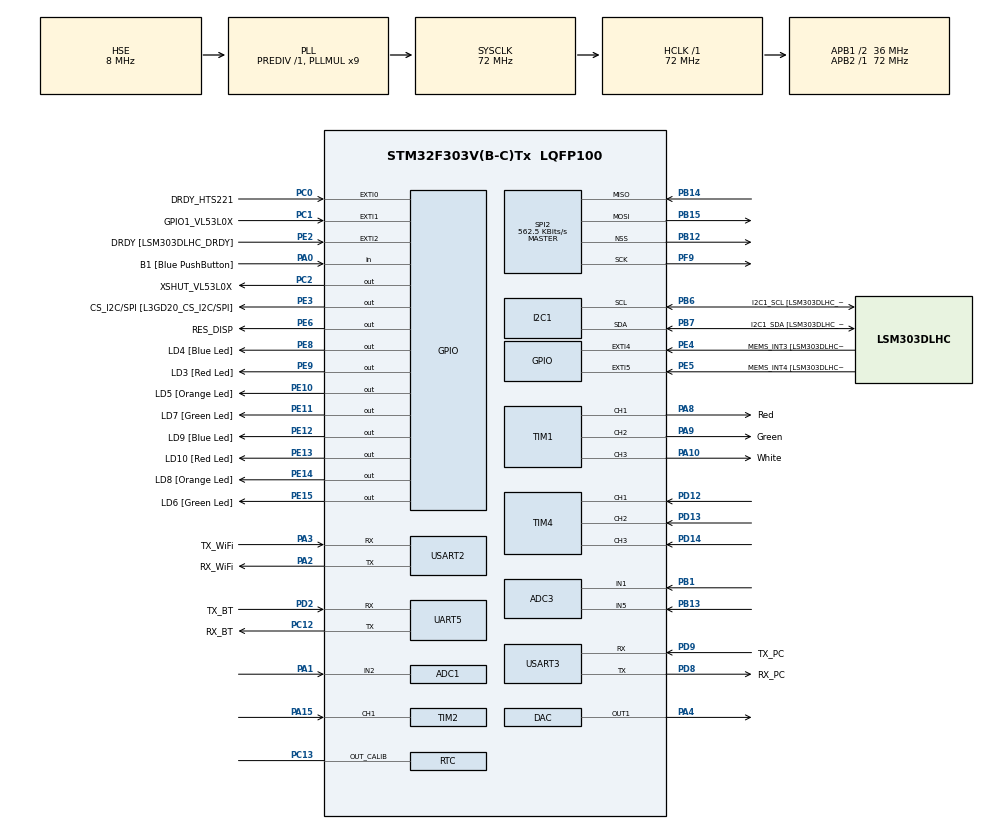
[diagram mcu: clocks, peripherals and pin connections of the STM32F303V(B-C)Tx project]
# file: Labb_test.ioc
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ADC1.Channel-0\#ChannelRegularConversion=ADC_CHANNEL_2
ADC1.NbrOfConversionFlag=1
ADC1.Offset-0\#ChannelRegularConversion=0
ADC1.OffsetNumber-0\#ChannelRegularConversion=ADC_OFFSET_NONE
ADC1.Rank-0\#ChannelRegularConversion=1
ADC1.SamplingTime-0\#ChannelRegularConversion=ADC_SAMPLETIME_1CYCLE_5
ADC1.master=1
ADC3.Channel-0\#ChannelRegularConversion=ADC_CHANNEL_1
ADC3.NbrOfConversionFlag=1
ADC3.Offset-0\#ChannelRegularConversion=0
ADC3.OffsetNumber-0\#ChannelRegularConversion=ADC_OFFSET_NONE
ADC3.Rank-0\#ChannelRegularConversion=1
ADC3.SamplingTime-0\#ChannelRegularConversion=ADC_SAMPLETIME_1CYCLE_5
ADC3.master=1
I2C1.Timing-I2C=0x2000090E
Mcu.Family=STM32F3
Mcu.Name=STM32F303V(B-C)Tx
Mcu.Package=LQFP100
NVIC.PriorityGroup=NVIC_PRIORITYGROUP_0
PA0.GPIO_Label=B1 [Blue PushButton]
PA0.Signal=GPIO_Input
PA1.Mode=IN2-Single-Ended
PA1.Signal=ADC1_IN2
PA10.GPIO_Label=White
PA10.Signal=S_TIM1_CH3
PA11.GPIO_Label=DM
PA11.Signal=USB_DM
PA12.GPIO_Label=DP
PA12.Signal=USB_DP
PA13.GPIO_Label=SWDIO
PA13.Mode=Serial_Wire
PA13.Signal=SYS_JTMS-SWDIO
PA14.GPIO_Label=SWCLK
PA14.Mode=Serial_Wire
PA14.Signal=SYS_JTCK-SWCLK
PA15.Signal=S_TIM2_CH1_ETR
PA2.GPIO_Label=RX_WiFi
PA2.Mode=Asynchronous
PA2.Signal=USART2_TX
PA3.GPIO_Label=TX_WiFi
PA3.Mode=Asynchronous
PA3.Signal=USART2_RX
PA4.Signal=COMP_DAC1_group
PA5.GPIO_Label=SPI1_SCK [L3GD20_SCL/SPC]
PA5.Signal=SPI1_SCK
PA6.GPIO_Label=SPI1_MISO [L3GD20_SA0/SDO]
PA6.Signal=SPI1_MISO
PA7.GPIO_Label=SPI1_MISO [L3GD20_SDA/SDI/SDO]
PA7.Signal=SPI1_MOSI
PA8.GPIO_Label=Red
PA8.Signal=S_TIM1_CH1
PA9.GPIO_Label=Green
PA9.Signal=S_TIM1_CH2
PB1.Mode=IN1-Single-Ended
PB1.Signal=ADC3_IN1
PB12.Mode=NSS_Signal_Hard_Output
PB12.Signal=SPI2_NSS
PB13.Mode=IN5-Single-Ended
PB13.Signal=ADC3_IN5
PB14.Mode=Full_Duplex_Master
PB14.Signal=SPI2_MISO
PB15.Mode=Full_Duplex_Master
PB15.Signal=SPI2_MOSI
PB3.GPIO_Label=SWO
PB3.Signal=SYS_JTDO-TRACESWO
PB6.GPIO_Label=I2C1_SCL [LSM303DLHC_SCL]
PB6.Mode=I2C
PB6.Signal=I2C1_SCL
PB7.GPIO_Label=I2C1_SDA [LSM303DLHC_SDA]
PB7.Mode=I2C
PB7.Signal=I2C1_SDA
PC0.GPIO_Label=DRDY_HTS221
PC0.Signal=GPXTI0
PC1.GPIO_Label=GPIO1_VL53L0X
PC1.Signal=GPXTI1
PC12.GPIO_Label=RX_BT
PC12.Mode=Asynchronous
PC12.Signal=UART5_TX
PC13.Mode=Calibration_1Hz
PC13.Signal=RTC_OUT_CALIB
PC14-OSC32_IN.GPIO_Label=OSC32_IN
PC14-OSC32_IN.Mode=LSE-External-Oscillator
PC14-OSC32_IN.Signal=RCC_OSC32_IN
PC15-OSC32_OUT.GPIO_Label=OSC32_OUT
PC15-OSC32_OUT.Mode=LSE-External-Oscillator
PC15-OSC32_OUT.Signal=RCC_OSC32_OUT
PC2.GPIO_Label=XSHUT_VL53L0X
PC2.Signal=GPIO_Output
PD12.Signal=S_TIM4_CH1
PD13.Signal=S_TIM4_CH2
PD14.Signal=S_TIM4_CH3
PD2.GPIO_Label=TX_BT
PD2.Mode=Asynchronous
PD2.Signal=UART5_RX
PD8.GPIO_Label=RX_PC
PD8.Mode=Asynchronous
PD8.Signal=USART3_TX
PD9.GPIO_Label=TX_PC
PD9.Mode=Asynchronous
PD9.Signal=USART3_RX
PE10.GPIO_Label=LD5 [Orange Led]
PE10.Signal=GPIO_Output
PE11.GPIO_Label=LD7 [Green Led]
PE11.Signal=GPIO_Output
PE12.GPIO_Label=LD9 [Blue Led]
PE12.Signal=GPIO_Output
PE13.GPIO_Label=LD10 [Red Led]
PE13.Signal=GPIO_Output
PE14.GPIO_Label=LD8 [Orange Led]
PE14.Signal=GPIO_Output
PE15.GPIO_Label=LD6 [Green Led]
PE15.Signal=GPIO_Output
PE2.GPIO_Label=DRDY [LSM303DLHC_DRDY]
PE2.GPIO_ModeDefaultEXTI=GPIO_MODE_EVT_RISING
PE2.Signal=GPXTI2
PE3.GPIO_Label=CS_I2C/SPI [L3GD20_CS_I2C/SPI]
PE3.Signal=GPIO_Output
PE4.GPIO_Label=MEMS_INT3 [LSM303DLHC_INT1]
PE4.GPIO_ModeDefaultEXTI=GPIO_MODE_EVT_RISING
PE4.Signal=GPXTI4
PE5.GPIO_Label=MEMS_INT4 [LSM303DLHC_INT2]
PE5.GPIO_ModeDefaultEXTI=GPIO_MODE_EVT_RISING
PE5.Signal=GPXTI5
PE6.GPIO_Label=RES_DISP
PE6.Signal=GPIO_Output
PE8.GPIO_Label=LD4 [Blue Led]
PE8.Signal=GPIO_Output
PE9.GPIO_Label=LD3 [Red Led]
PE9.Signal=GPIO_Output
PF0-OSC_IN.GPIO_Label=OSC_IN
PF0-OSC_IN.Mode=HSE-External-Oscillator
PF0-OSC_IN.Signal=RCC_OSC_IN
PF1-OSC_OUT.GPIO_Label=OSC_OUT
PF1-OSC_OUT.Mode=HSE-External-Oscillator
PF1-OSC_OUT.Signal=RCC_OSC_OUT
PF9.Mode=Full_Duplex_Master
PF9.Signal=SPI2_SCK
ProjectManager.HeapSize=0x200
ProjectManager.StackSize=0x400
ProjectManager.TargetToolchain=EWARM V8
RCC.AHBFreq_Value=72000000
RCC.APB1CLKDivider=RCC_HCLK_DIV2
RCC.APB1Freq_Value=36000000
RCC.APB1TimFreq_Value=72000000
RCC.APB2Freq_Value=72000000
RCC.APB2TimFreq_Value=72000000
RCC.CortexFreq_Value=72000000
RCC.HCLKFreq_Value=72000000
RCC.HSE_VALUE=8000000
RCC.HSI_VALUE=8000000
RCC.PLLMUL=RCC_PLL_MUL9
RCC.PLLSourceVirtual=RCC_PLLSOURCE_HSE
RCC.SYSCLKFreq_VALUE=72000000
RCC.SYSCLKSourceVirtual=RCC_SYSCLKSOURCE_PLLCLK
RCC.USBFreq_Value=72000000
SH.COMP_DAC1_group.0=DAC_OUT1,DAC_OUT1
SH.S_TIM1_CH1.0=TIM1_CH1,Output Compare1 CH1
SH.S_TIM1_CH2.0=TIM1_CH2,Output Compare2 CH2
SH.S_TIM1_CH3.0=TIM1_CH3,Output Compare3 CH3
SH.S_TIM2_CH1_ETR.0=TIM2_CH1,Input_Capture1_from_TI1
SH.S_TIM4_CH1.0=TIM4_CH1,Input_Capture1_from_TI1
SH.S_TIM4_CH2.0=TIM4_CH2,Input_Capture2_from_TI2
SH.S_TIM4_CH3.0=TIM4_CH3,Input_Capture3_from_TI3
SPI2.BaudRatePrescaler=SPI_BAUDRATEPRESCALER_64
SPI2.CLKPhase=SPI_PHASE_2EDGE
SPI2.CLKPolarity=SPI_POLARITY_HIGH
SPI2.CalculateBaudRate=562.5 KBits/s
SPI2.DataSize=SPI_DATASIZE_8BIT
SPI2.Direction=SPI_DIRECTION_2LINES
SPI2.FirstBit=SPI_FIRSTBIT_LSB
SPI2.Mode=SPI_MODE_MASTER
SPI2.VirtualNSS=VM_NSSHARD
SPI2.VirtualType=VM_MASTER
TIM1.Channel-Output\ Compare1\ CH1=TIM_CHANNEL_1
TIM1.Channel-Output\ Compare2\ CH2=TIM_CHANNEL_2
TIM1.Channel-Output\ Compare3\ CH3=TIM_CHANNEL_3
TIM2.Channel-Input_Capture1_from_TI1=TIM_CHANNEL_1
TIM4.Channel-Input_Capture1_from_TI1=TIM_CHANNEL_1
TIM4.Channel-Input_Capture2_from_TI2=TIM_CHANNEL_2
TIM4.Channel-Input_Capture3_from_TI3=TIM_CHANNEL_3
USART2.VirtualMode-Asynchronous=VM_ASYNC
USART3.VirtualMode-Asynchronous=VM_ASYNC
VP_RTC_VS_RTC_Activate.Mode=RTC_Enabled
board=STM32F3DISCOVERY

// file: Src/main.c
/**
  ******************************************************************************
  * @file           : main.c
  * @brief          : Main program body
  ******************************************************************************
  ** This notice applies to any and all portions of this file
  * that are not between comment pairs USER CODE BEGIN and
  * USER CODE END. Other portions of this file, whether
  * inserted by the user or by software development tools
  * are owned by their respective copyright owners.
  *
  * COPYRIGHT(c) 2019 STMicroelectronics
  *
  * Redistribution and use in source and binary forms, with or without modification,
  * are permitted provided that the following conditions are met:
  *   1. Redistributions of source code must retain the above copyright notice,
  *      this list of conditions and the following disclaimer.
  *   2. Redistributions in binary form must reproduce the above copyright notice,
  *      this list of conditions and the following disclaimer in the documentation
  *      and/or other materials provided with the distribution.
  *   3. Neither the name of STMicroelectronics nor the names of its contributors
  *      may be used to endorse or promote products derived from this software
  *      without specific prior written permission.
  *
  * THIS SOFTWARE IS PROVIDED BY THE COPYRIGHT HOLDERS AND CONTRIBUTORS "AS IS"
  * AND ANY EXPRESS OR IMPLIED WARRANTIES, INCLUDING, BUT NOT LIMITED TO, THE
  * IMPLIED WARRANTIES OF MERCHANTABILITY AND FITNESS FOR A PARTICULAR PURPOSE ARE
  * DISCLAIMED. IN NO EVENT SHALL THE COPYRIGHT HOLDER OR CONTRIBUTORS BE LIABLE
  * FOR ANY DIRECT, INDIRECT, INCIDENTAL, SPECIAL, EXEMPLARY, OR CONSEQUENTIAL
  * DAMAGES (INCLUDING, BUT NOT LIMITED TO, PROCUREMENT OF SUBSTITUTE GOODS OR
  * SERVICES; LOSS OF USE, DATA, OR PROFITS; OR BUSINESS INTERRUPTION) HOWEVER
  * CAUSED AND ON ANY THEORY OF LIABILITY, WHETHER IN CONTRACT, STRICT LIABILITY,
  * OR TORT (INCLUDING NEGLIGENCE OR OTHERWISE) ARISING IN ANY WAY OUT OF THE USE
  * OF THIS SOFTWARE, EVEN IF ADVISED OF THE POSSIBILITY OF SUCH DAMAGE.
  *
  ******************************************************************************
  */
#include "main.h"
#include "stm32f3xx_hal.h"

ADC_HandleTypeDef hadc1;
ADC_HandleTypeDef hadc3;

DAC_HandleTypeDef hdac;

I2C_HandleTypeDef hi2c1;

RTC_HandleTypeDef hrtc;

SPI_HandleTypeDef hspi2;

TIM_HandleTypeDef htim1;
TIM_HandleTypeDef htim2;
TIM_HandleTypeDef htim4;

UART_HandleTypeDef huart5;
UART_HandleTypeDef huart2;
UART_HandleTypeDef huart3;

/* USER CODE BEGIN PV */
/* Private variables ---------------------------------------------------------*/

/* USER CODE END PV */

void SystemClock_Config(void);
static void MX_GPIO_Init(void);
static void MX_I2C1_Init(void);
static void MX_TIM2_Init(void);
static void MX_ADC3_Init(void);
static void MX_ADC1_Init(void);
static void MX_UART5_Init(void);
static void MX_USART2_UART_Init(void);
static void MX_SPI2_Init(void);
static void MX_TIM1_Init(void);
static void MX_TIM4_Init(void);
static void MX_USART3_UART_Init(void);
static void MX_DAC_Init(void);
static void MX_RTC_Init(void);

void HAL_TIM_MspPostInit(TIM_HandleTypeDef *htim);

/* USER CODE BEGIN PFP */
/* Private function prototypes -----------------------------------------------*/

/* USER CODE END PFP */

int main(void)
{

  /* MCU Configuration----------------------------------------------------------*/

  /* Reset of all peripherals, Initializes the Flash interface and the Systick. */
  HAL_Init();

  /* Configure the system clock */
  SystemClock_Config();

  /* Initialize all configured peripherals */
  MX_GPIO_Init();
  MX_I2C1_Init();
  MX_TIM2_Init();
  MX_ADC3_Init();
  MX_ADC1_Init();
  MX_UART5_Init();
  MX_USART2_UART_Init();
  MX_SPI2_Init();
  MX_TIM1_Init();
  MX_TIM4_Init();
  MX_USART3_UART_Init();
  MX_DAC_Init();
  MX_RTC_Init();
  /* USER CODE BEGIN 2 */

    initDisplay();
    sendDisplay(0,0,0);

  /* USER CODE END 2 */

  /* Infinite loop */
  while (1)
  {

  }

}

void SystemClock_Config(void)
{

  RCC_OscInitTypeDef RCC_OscInitStruct;
  RCC_ClkInitTypeDef RCC_ClkInitStruct;
  RCC_PeriphCLKInitTypeDef PeriphClkInit;

    /**Initializes the CPU, AHB and APB busses clocks
    */
  RCC_OscInitStruct.OscillatorType = RCC_OSCILLATORTYPE_HSI|RCC_OSCILLATORTYPE_LSI
                              |RCC_OSCILLATORTYPE_HSE;
  RCC_OscInitStruct.HSEState = RCC_HSE_ON;
  RCC_OscInitStruct.HSEPredivValue = RCC_HSE_PREDIV_DIV1;
  RCC_OscInitStruct.HSIState = RCC_HSI_ON;
  RCC_OscInitStruct.HSICalibrationValue = 16;
  RCC_OscInitStruct.LSIState = RCC_LSI_ON;
  RCC_OscInitStruct.PLL.PLLState = RCC_PLL_ON;
  RCC_OscInitStruct.PLL.PLLSource = RCC_PLLSOURCE_HSE;
  RCC_OscInitStruct.PLL.PLLMUL = RCC_PLL_MUL9;
  if (HAL_RCC_OscConfig(&RCC_OscInitStruct) != HAL_OK)
  {
    _Error_Handler(__FILE__, __LINE__);
  }

    /**Initializes the CPU, AHB and APB busses clocks
    */
  RCC_ClkInitStruct.ClockType = RCC_CLOCKTYPE_HCLK|RCC_CLOCKTYPE_SYSCLK
                              |RCC_CLOCKTYPE_PCLK1|RCC_CLOCKTYPE_PCLK2;
  RCC_ClkInitStruct.SYSCLKSource = RCC_SYSCLKSOURCE_PLLCLK;
  RCC_ClkInitStruct.AHBCLKDivider = RCC_SYSCLK_DIV1;
  RCC_ClkInitStruct.APB1CLKDivider = RCC_HCLK_DIV2;
  RCC_ClkInitStruct.APB2CLKDivider = RCC_HCLK_DIV1;

  if (HAL_RCC_ClockConfig(&RCC_ClkInitStruct, FLASH_LATENCY_2) != HAL_OK)
  {
    _Error_Handler(__FILE__, __LINE__);
  }

  PeriphClkInit.PeriphClockSelection = RCC_PERIPHCLK_USART2|RCC_PERIPHCLK_USART3
                              |RCC_PERIPHCLK_UART5|RCC_PERIPHCLK_I2C1
                              |RCC_PERIPHCLK_RTC|RCC_PERIPHCLK_TIM1
                              |RCC_PERIPHCLK_ADC12|RCC_PERIPHCLK_ADC34;
  PeriphClkInit.Usart2ClockSelection = RCC_USART2CLKSOURCE_PCLK1;
  PeriphClkInit.Usart3ClockSelection = RCC_USART3CLKSOURCE_PCLK1;
  PeriphClkInit.Uart5ClockSelection = RCC_UART5CLKSOURCE_PCLK1;
  PeriphClkInit.Adc12ClockSelection = RCC_ADC12PLLCLK_DIV1;
  PeriphClkInit.Adc34ClockSelection = RCC_ADC34PLLCLK_DIV1;
  PeriphClkInit.I2c1ClockSelection = RCC_I2C1CLKSOURCE_HSI;
  PeriphClkInit.RTCClockSelection = RCC_RTCCLKSOURCE_LSI;
  PeriphClkInit.Tim1ClockSelection = RCC_TIM1CLK_HCLK;
  if (HAL_RCCEx_PeriphCLKConfig(&PeriphClkInit) != HAL_OK)
  {
    _Error_Handler(__FILE__, __LINE__);
  }

    /**Configure the Systick interrupt time
    */
  HAL_SYSTICK_Config(HAL_RCC_GetHCLKFreq()/1000);

    /**Configure the Systick
    */
  HAL_SYSTICK_CLKSourceConfig(SYSTICK_CLKSOURCE_HCLK);

  /* SysTick_IRQn interrupt configuration */
  HAL_NVIC_SetPriority(SysTick_IRQn, 0, 0);
}
   uint8_t data[3]={0x00,0x00,0x00};

  void initDisplay(void)
  {
        HAL_GPIO_WritePin(GPIOE,GPIO_PIN_6,GPIO_PIN_RESET);
        HAL_GPIO_WritePin(GPIOE,GPIO_PIN_6,GPIO_PIN_SET);
        sendDisplay(0,0,0x3A);/* Function Set -> 8-bit data RE=1 */
	sendDisplay(0,0,0x09); /* 4 line display */
	sendDisplay(0,0,0x06); /* bottom view */
	sendDisplay(0,0,0x1E); /* BS1 = 1 */
	sendDisplay(0,0,0x39); /* Function Set -> 8-bit data RE=0 */
	sendDisplay(0,0,0x1B); /* Internal OSC */
	sendDisplay(0,0,0x6E); /* Follower control */
	sendDisplay(0,0,0x56); /* Power control */
	sendDisplay(0,0,0x7A); /* Contrast Set */
	sendDisplay(0,0,0x38); /* Function Set -> 8-bit data IS=0 */
	sendDisplay(0,0,0x0F); /* Display on, Cursor on, Blink on */// 0000 1100 = 0C
        sendDisplay(0,0,0x01); // clear display
        sendDisplay(1,0,0x43);
  }

  void sendDisplay(uint8_t rs,uint8_t rw,uint8_t db)
  {
	data[0] = 0x1F | (rs << 6) | (rw << 5);
	data[1] = db & 0x0f;
	data[2] = (db & 0xf0) >> 4;
	HAL_SPI_Transmit(&hspi2,data,3,1000);

  }

/* ADC1 init function */
static void MX_ADC1_Init(void)
{

  ADC_MultiModeTypeDef multimode;
  ADC_ChannelConfTypeDef sConfig;

    /**Common config
    */
  hadc1.Instance = ADC1;
  hadc1.Init.ClockPrescaler = ADC_CLOCK_ASYNC_DIV1;
  hadc1.Init.Resolution = ADC_RESOLUTION_12B;
  hadc1.Init.ScanConvMode = ADC_SCAN_DISABLE;
  hadc1.Init.ContinuousConvMode = DISABLE;
  hadc1.Init.DiscontinuousConvMode = DISABLE;
  hadc1.Init.ExternalTrigConvEdge = ADC_EXTERNALTRIGCONVEDGE_NONE;
  hadc1.Init.ExternalTrigConv = ADC_SOFTWARE_START;
  hadc1.Init.DataAlign = ADC_DATAALIGN_RIGHT;
  hadc1.Init.NbrOfConversion = 1;
  hadc1.Init.DMAContinuousRequests = DISABLE;
  hadc1.Init.EOCSelection = ADC_EOC_SINGLE_CONV;
  hadc1.Init.LowPowerAutoWait = DISABLE;
  hadc1.Init.Overrun = ADC_OVR_DATA_OVERWRITTEN;
  if (HAL_ADC_Init(&hadc1) != HAL_OK)
  {
    _Error_Handler(__FILE__, __LINE__);
  }

    /**Configure the ADC multi-mode
    */
  multimode.Mode = ADC_MODE_INDEPENDENT;
  if (HAL_ADCEx_MultiModeConfigChannel(&hadc1, &multimode) != HAL_OK)
  {
    _Error_Handler(__FILE__, __LINE__);
  }

    /**Configure Regular Channel
    */
  sConfig.Channel = ADC_CHANNEL_2;
  sConfig.Rank = ADC_REGULAR_RANK_1;
  sConfig.SingleDiff = ADC_SINGLE_ENDED;
  sConfig.SamplingTime = ADC_SAMPLETIME_1CYCLE_5;
  sConfig.OffsetNumber = ADC_OFFSET_NONE;
  sConfig.Offset = 0;
  if (HAL_ADC_ConfigChannel(&hadc1, &sConfig) != HAL_OK)
  {
    _Error_Handler(__FILE__, __LINE__);
  }

}

/* ADC3 init function */
static void MX_ADC3_Init(void)
{

  ADC_MultiModeTypeDef multimode;
  ADC_ChannelConfTypeDef sConfig;

    /**Common config
    */
  hadc3.Instance = ADC3;
  hadc3.Init.ClockPrescaler = ADC_CLOCK_ASYNC_DIV1;
  hadc3.Init.Resolution = ADC_RESOLUTION_12B;
  hadc3.Init.ScanConvMode = ADC_SCAN_DISABLE;
  hadc3.Init.ContinuousConvMode = DISABLE;
  hadc3.Init.DiscontinuousConvMode = DISABLE;
  hadc3.Init.ExternalTrigConvEdge = ADC_EXTERNALTRIGCONVEDGE_NONE;
  hadc3.Init.ExternalTrigConv = ADC_SOFTWARE_START;
  hadc3.Init.DataAlign = ADC_DATAALIGN_RIGHT;
  hadc3.Init.NbrOfConversion = 1;
  hadc3.Init.DMAContinuousRequests = DISABLE;
  hadc3.Init.EOCSelection = ADC_EOC_SINGLE_CONV;
  hadc3.Init.LowPowerAutoWait = DISABLE;
  hadc3.Init.Overrun = ADC_OVR_DATA_OVERWRITTEN;
  if (HAL_ADC_Init(&hadc3) != HAL_OK)
  {
    _Error_Handler(__FILE__, __LINE__);
  }

    /**Configure the ADC multi-mode
    */
  multimode.Mode = ADC_MODE_INDEPENDENT;
  if (HAL_ADCEx_MultiModeConfigChannel(&hadc3, &multimode) != HAL_OK)
  {
    _Error_Handler(__FILE__, __LINE__);
  }

    /**Configure Regular Channel
    */
  sConfig.Channel = ADC_CHANNEL_1;
  sConfig.Rank = ADC_REGULAR_RANK_1;
  sConfig.SingleDiff = ADC_SINGLE_ENDED;
  sConfig.SamplingTime = ADC_SAMPLETIME_1CYCLE_5;
  sConfig.OffsetNumber = ADC_OFFSET_NONE;
  sConfig.Offset = 0;
  if (HAL_ADC_ConfigChannel(&hadc3, &sConfig) != HAL_OK)
  {
    _Error_Handler(__FILE__, __LINE__);
  }

}

/* DAC init function */
static void MX_DAC_Init(void)
{

  DAC_ChannelConfTypeDef sConfig;

    /**DAC Initialization
    */
  hdac.Instance = DAC;
  if (HAL_DAC_Init(&hdac) != HAL_OK)
  {
    _Error_Handler(__FILE__, __LINE__);
  }

    /**DAC channel OUT1 config
    */
  sConfig.DAC_Trigger = DAC_TRIGGER_NONE;
  sConfig.DAC_OutputBuffer = DAC_OUTPUTBUFFER_ENABLE;
  if (HAL_DAC_ConfigChannel(&hdac, &sConfig, DAC_CHANNEL_1) != HAL_OK)
  {
    _Error_Handler(__FILE__, __LINE__);
  }

}

/* I2C1 init function */
static void MX_I2C1_Init(void)
{

  hi2c1.Instance = I2C1;
  hi2c1.Init.Timing = 0x2000090E;
  hi2c1.Init.OwnAddress1 = 0;
  hi2c1.Init.AddressingMode = I2C_ADDRESSINGMODE_7BIT;
  hi2c1.Init.DualAddressMode = I2C_DUALADDRESS_DISABLE;
  hi2c1.Init.OwnAddress2 = 0;
  hi2c1.Init.OwnAddress2Masks = I2C_OA2_NOMASK;
  hi2c1.Init.GeneralCallMode = I2C_GENERALCALL_DISABLE;
  hi2c1.Init.NoStretchMode = I2C_NOSTRETCH_DISABLE;
  if (HAL_I2C_Init(&hi2c1) != HAL_OK)
  {
    _Error_Handler(__FILE__, __LINE__);
  }

    /**Configure Analogue filter
    */
  if (HAL_I2CEx_ConfigAnalogFilter(&hi2c1, I2C_ANALOGFILTER_ENABLE) != HAL_OK)
  {
    _Error_Handler(__FILE__, __LINE__);
  }

    /**Configure Digital filter
    */
  if (HAL_I2CEx_ConfigDigitalFilter(&hi2c1, 0) != HAL_OK)
  {
    _Error_Handler(__FILE__, __LINE__);
  }

}

/* RTC init function */
static void MX_RTC_Init(void)
{

    /**Initialize RTC Only
    */
  hrtc.Instance = RTC;
  hrtc.Init.HourFormat = RTC_HOURFORMAT_24;
  hrtc.Init.AsynchPrediv = 127;
  hrtc.Init.SynchPrediv = 255;
  hrtc.Init.OutPut = RTC_OUTPUT_DISABLE;
  hrtc.Init.OutPutPolarity = RTC_OUTPUT_POLARITY_HIGH;
  hrtc.Init.OutPutType = RTC_OUTPUT_TYPE_OPENDRAIN;
  if (HAL_RTC_Init(&hrtc) != HAL_OK)
  {
    _Error_Handler(__FILE__, __LINE__);
  }

    /**Enable Calibration
    */
  if (HAL_RTCEx_SetCalibrationOutPut(&hrtc, RTC_CALIBOUTPUT_1HZ) != HAL_OK)
  {
    _Error_Handler(__FILE__, __LINE__);
  }

}

/* SPI2 init function */
static void MX_SPI2_Init(void)
{

  /* SPI2 parameter configuration*/
  hspi2.Instance = SPI2;
  hspi2.Init.Mode = SPI_MODE_MASTER;
  hspi2.Init.Direction = SPI_DIRECTION_2LINES;
  hspi2.Init.DataSize = SPI_DATASIZE_8BIT;
  hspi2.Init.CLKPolarity = SPI_POLARITY_HIGH;
  hspi2.Init.CLKPhase = SPI_PHASE_2EDGE;
  hspi2.Init.NSS = SPI_NSS_HARD_OUTPUT;
  hspi2.Init.BaudRatePrescaler = SPI_BAUDRATEPRESCALER_64;
  hspi2.Init.FirstBit = SPI_FIRSTBIT_LSB;
  hspi2.Init.TIMode = SPI_TIMODE_DISABLE;
  hspi2.Init.CRCCalculation = SPI_CRCCALCULATION_DISABLE;
  hspi2.Init.CRCPolynomial = 7;
  hspi2.Init.CRCLength = SPI_CRC_LENGTH_DATASIZE;
  hspi2.Init.NSSPMode = SPI_NSS_PULSE_DISABLE;
  if (HAL_SPI_Init(&hspi2) != HAL_OK)
  {
    _Error_Handler(__FILE__, __LINE__);
  }

}

/* TIM1 init function */
static void MX_TIM1_Init(void)
{

  TIM_MasterConfigTypeDef sMasterConfig;
  TIM_OC_InitTypeDef sConfigOC;
  TIM_BreakDeadTimeConfigTypeDef sBreakDeadTimeConfig;

  htim1.Instance = TIM1;
  htim1.Init.Prescaler = 0;
  htim1.Init.CounterMode = TIM_COUNTERMODE_UP;
  htim1.Init.Period = 0;
  htim1.Init.ClockDivision = TIM_CLOCKDIVISION_DIV1;
  htim1.Init.RepetitionCounter = 0;
  htim1.Init.AutoReloadPreload = TIM_AUTORELOAD_PRELOAD_DISABLE;
  if (HAL_TIM_OC_Init(&htim1) != HAL_OK)
  {
    _Error_Handler(__FILE__, __LINE__);
  }

  sMasterConfig.MasterOutputTrigger = TIM_TRGO_RESET;
  sMasterConfig.MasterOutputTrigger2 = TIM_TRGO2_RESET;
  sMasterConfig.MasterSlaveMode = TIM_MASTERSLAVEMODE_DISABLE;
  if (HAL_TIMEx_MasterConfigSynchronization(&htim1, &sMasterConfig) != HAL_OK)
  {
    _Error_Handler(__FILE__, __LINE__);
  }

  sConfigOC.OCMode = TIM_OCMODE_TIMING;
  sConfigOC.Pulse = 0;
  sConfigOC.OCPolarity = TIM_OCPOLARITY_HIGH;
  sConfigOC.OCNPolarity = TIM_OCNPOLARITY_HIGH;
  sConfigOC.OCFastMode = TIM_OCFAST_DISABLE;
  sConfigOC.OCIdleState = TIM_OCIDLESTATE_RESET;
  sConfigOC.OCNIdleState = TIM_OCNIDLESTATE_RESET;
  if (HAL_TIM_OC_ConfigChannel(&htim1, &sConfigOC, TIM_CHANNEL_1) != HAL_OK)
  {
    _Error_Handler(__FILE__, __LINE__);
  }

  if (HAL_TIM_OC_ConfigChannel(&htim1, &sConfigOC, TIM_CHANNEL_2) != HAL_OK)
  {
    _Error_Handler(__FILE__, __LINE__);
  }

  if (HAL_TIM_OC_ConfigChannel(&htim1, &sConfigOC, TIM_CHANNEL_3) != HAL_OK)
  {
    _Error_Handler(__FILE__, __LINE__);
  }

  sBreakDeadTimeConfig.OffStateRunMode = TIM_OSSR_DISABLE;
  sBreakDeadTimeConfig.OffStateIDLEMode = TIM_OSSI_DISABLE;
  sBreakDeadTimeConfig.LockLevel = TIM_LOCKLEVEL_OFF;
  sBreakDeadTimeConfig.DeadTime = 0;
  sBreakDeadTimeConfig.BreakState = TIM_BREAK_DISABLE;
  sBreakDeadTimeConfig.BreakPolarity = TIM_BREAKPOLARITY_HIGH;
  sBreakDeadTimeConfig.BreakFilter = 0;
  sBreakDeadTimeConfig.Break2State = TIM_BREAK2_DISABLE;
  sBreakDeadTimeConfig.Break2Polarity = TIM_BREAK2POLARITY_HIGH;
  sBreakDeadTimeConfig.Break2Filter = 0;
  sBreakDeadTimeConfig.AutomaticOutput = TIM_AUTOMATICOUTPUT_DISABLE;
  if (HAL_TIMEx_ConfigBreakDeadTime(&htim1, &sBreakDeadTimeConfig) != HAL_OK)
  {
    _Error_Handler(__FILE__, __LINE__);
  }

  HAL_TIM_MspPostInit(&htim1);

}

/* TIM2 init function */
static void MX_TIM2_Init(void)
{

  TIM_MasterConfigTypeDef sMasterConfig;
  TIM_IC_InitTypeDef sConfigIC;

  htim2.Instance = TIM2;
  htim2.Init.Prescaler = 0;
  htim2.Init.CounterMode = TIM_COUNTERMODE_UP;
  htim2.Init.Period = 0;
  htim2.Init.ClockDivision = TIM_CLOCKDIVISION_DIV1;
  htim2.Init.AutoReloadPreload = TIM_AUTORELOAD_PRELOAD_DISABLE;
  if (HAL_TIM_IC_Init(&htim2) != HAL_OK)
  {
    _Error_Handler(__FILE__, __LINE__);
  }

  sMasterConfig.MasterOutputTrigger = TIM_TRGO_RESET;
  sMasterConfig.MasterSlaveMode = TIM_MASTERSLAVEMODE_DISABLE;
  if (HAL_TIMEx_MasterConfigSynchronization(&htim2, &sMasterConfig) != HAL_OK)
  {
    _Error_Handler(__FILE__, __LINE__);
  }

  sConfigIC.ICPolarity = TIM_INPUTCHANNELPOLARITY_RISING;
  sConfigIC.ICSelection = TIM_ICSELECTION_DIRECTTI;
  sConfigIC.ICPrescaler = TIM_ICPSC_DIV1;
  sConfigIC.ICFilter = 0;
  if (HAL_TIM_IC_ConfigChannel(&htim2, &sConfigIC, TIM_CHANNEL_1) != HAL_OK)
  {
    _Error_Handler(__FILE__, __LINE__);
  }

}

/* TIM4 init function */
static void MX_TIM4_Init(void)
{

  TIM_MasterConfigTypeDef sMasterConfig;
  TIM_IC_InitTypeDef sConfigIC;

  htim4.Instance = TIM4;
  htim4.Init.Prescaler = 0;
  htim4.Init.CounterMode = TIM_COUNTERMODE_UP;
  htim4.Init.Period = 0;
  htim4.Init.ClockDivision = TIM_CLOCKDIVISION_DIV1;
  htim4.Init.AutoReloadPreload = TIM_AUTORELOAD_PRELOAD_DISABLE;
  if (HAL_TIM_IC_Init(&htim4) != HAL_OK)
  {
    _Error_Handler(__FILE__, __LINE__);
  }

  sMasterConfig.MasterOutputTrigger = TIM_TRGO_RESET;
  sMasterConfig.MasterSlaveMode = TIM_MASTERSLAVEMODE_DISABLE;
  if (HAL_TIMEx_MasterConfigSynchronization(&htim4, &sMasterConfig) != HAL_OK)
  {
    _Error_Handler(__FILE__, __LINE__);
  }

  sConfigIC.ICPolarity = TIM_INPUTCHANNELPOLARITY_RISING;
  sConfigIC.ICSelection = TIM_ICSELECTION_DIRECTTI;
  sConfigIC.ICPrescaler = TIM_ICPSC_DIV1;
  sConfigIC.ICFilter = 0;
  if (HAL_TIM_IC_ConfigChannel(&htim4, &sConfigIC, TIM_CHANNEL_1) != HAL_OK)
  {
    _Error_Handler(__FILE__, __LINE__);
  }

  if (HAL_TIM_IC_ConfigChannel(&htim4, &sConfigIC, TIM_CHANNEL_2) != HAL_OK)
  {
    _Error_Handler(__FILE__, __LINE__);
  }

  if (HAL_TIM_IC_ConfigChannel(&htim4, &sConfigIC, TIM_CHANNEL_3) != HAL_OK)
  {
    _Error_Handler(__FILE__, __LINE__);
  }

}

/* UART5 init function */
static void MX_UART5_Init(void)
{

  huart5.Instance = UART5;
  huart5.Init.BaudRate = 115200;
  huart5.Init.WordLength = UART_WORDLENGTH_8B;
  huart5.Init.StopBits = UART_STOPBITS_1;
  huart5.Init.Parity = UART_PARITY_NONE;
  huart5.Init.Mode = UART_MODE_TX_RX;
  huart5.Init.HwFlowCtl = UART_HWCONTROL_NONE;
  huart5.Init.OverSampling = UART_OVERSAMPLING_16;
  huart5.Init.OneBitSampling = UART_ONE_BIT_SAMPLE_DISABLE;
  huart5.AdvancedInit.AdvFeatureInit = UART_ADVFEATURE_NO_INIT;
  if (HAL_UART_Init(&huart5) != HAL_OK)
  {
    _Error_Handler(__FILE__, __LINE__);
  }

}

/* USART2 init function */
static void MX_USART2_UART_Init(void)
{

  huart2.Instance = USART2;
  huart2.Init.BaudRate = 38400;
  huart2.Init.WordLength = UART_WORDLENGTH_8B;
  huart2.Init.StopBits = UART_STOPBITS_1;
  huart2.Init.Parity = UART_PARITY_NONE;
  huart2.Init.Mode = UART_MODE_TX_RX;
  huart2.Init.HwFlowCtl = UART_HWCONTROL_NONE;
  huart2.Init.OverSampling = UART_OVERSAMPLING_16;
  huart2.Init.OneBitSampling = UART_ONE_BIT_SAMPLE_DISABLE;
  huart2.AdvancedInit.AdvFeatureInit = UART_ADVFEATURE_NO_INIT;
  if (HAL_UART_Init(&huart2) != HAL_OK)
  {
    _Error_Handler(__FILE__, __LINE__);
  }

}

/* USART3 init function */
static void MX_USART3_UART_Init(void)
{

  huart3.Instance = USART3;
  huart3.Init.BaudRate = 38400;
  huart3.Init.WordLength = UART_WORDLENGTH_8B;
  huart3.Init.StopBits = UART_STOPBITS_1;
  huart3.Init.Parity = UART_PARITY_NONE;
  huart3.Init.Mode = UART_MODE_TX_RX;
  huart3.Init.HwFlowCtl = UART_HWCONTROL_NONE;
  huart3.Init.OverSampling = UART_OVERSAMPLING_16;
  huart3.Init.OneBitSampling = UART_ONE_BIT_SAMPLE_DISABLE;
  huart3.AdvancedInit.AdvFeatureInit = UART_ADVFEATURE_NO_INIT;
  if (HAL_UART_Init(&huart3) != HAL_OK)
  {
    _Error_Handler(__FILE__, __LINE__);
  }

}

/** Configure pins as
        * Analog
        * Input
        * Output
        * EVENT_OUT
        * EXTI
     PA5   ------> SPI1_SCK
     PA6   ------> SPI1_MISO
     PA7   ------> SPI1_MOSI
     PA11   ------> USB_DM
     PA12   ------> USB_DP
*/
static void MX_GPIO_Init(void)
{

  GPIO_InitTypeDef GPIO_InitStruct;

  /* GPIO Ports Clock Enable */
  __HAL_RCC_GPIOE_CLK_ENABLE();
  __HAL_RCC_GPIOC_CLK_ENABLE();
  __HAL_RCC_GPIOF_CLK_ENABLE();
  __HAL_RCC_GPIOA_CLK_ENABLE();
  __HAL_RCC_GPIOB_CLK_ENABLE();
  __HAL_RCC_GPIOD_CLK_ENABLE();

  /*Configure GPIO pin Output Level */
  HAL_GPIO_WritePin(GPIOE, CS_I2C_SPI_Pin|RES_DISP_Pin|LD4_Pin|LD3_Pin
                          |LD5_Pin|LD7_Pin|LD9_Pin|LD10_Pin
                          |LD8_Pin|LD6_Pin, GPIO_PIN_RESET);

  /*Configure GPIO pin Output Level */
  HAL_GPIO_WritePin(XSHUT_VL53L0X_GPIO_Port, XSHUT_VL53L0X_Pin, GPIO_PIN_RESET);

  /*Configure GPIO pins : DRDY_Pin MEMS_INT3_Pin MEMS_INT4_Pin */
  GPIO_InitStruct.Pin = DRDY_Pin|MEMS_INT3_Pin|MEMS_INT4_Pin;
  GPIO_InitStruct.Mode = GPIO_MODE_EVT_RISING;
  GPIO_InitStruct.Pull = GPIO_NOPULL;
  HAL_GPIO_Init(GPIOE, &GPIO_InitStruct);

  /*Configure GPIO pins : CS_I2C_SPI_Pin RES_DISP_Pin LD4_Pin LD3_Pin
                           LD5_Pin LD7_Pin LD9_Pin LD10_Pin
                           LD8_Pin LD6_Pin */
  GPIO_InitStruct.Pin = CS_I2C_SPI_Pin|RES_DISP_Pin|LD4_Pin|LD3_Pin
                          |LD5_Pin|LD7_Pin|LD9_Pin|LD10_Pin
                          |LD8_Pin|LD6_Pin;
  GPIO_InitStruct.Mode = GPIO_MODE_OUTPUT_PP;
  GPIO_InitStruct.Pull = GPIO_NOPULL;
  GPIO_InitStruct.Speed = GPIO_SPEED_FREQ_LOW;
  HAL_GPIO_Init(GPIOE, &GPIO_InitStruct);

  /*Configure GPIO pins : DRDY_HTS221_Pin GPIO1_VL53L0X_Pin */
  GPIO_InitStruct.Pin = DRDY_HTS221_Pin|GPIO1_VL53L0X_Pin;
  GPIO_InitStruct.Mode = GPIO_MODE_IT_RISING;
  GPIO_InitStruct.Pull = GPIO_NOPULL;
  HAL_GPIO_Init(GPIOC, &GPIO_InitStruct);

  /*Configure GPIO pin : XSHUT_VL53L0X_Pin */
  GPIO_InitStruct.Pin = XSHUT_VL53L0X_Pin;
  GPIO_InitStruct.Mode = GPIO_MODE_OUTPUT_PP;
  GPIO_InitStruct.Pull = GPIO_NOPULL;
  GPIO_InitStruct.Speed = GPIO_SPEED_FREQ_LOW;
  HAL_GPIO_Init(XSHUT_VL53L0X_GPIO_Port, &GPIO_InitStruct);

  /*Configure GPIO pin : B1_Pin */
  GPIO_InitStruct.Pin = B1_Pin;
  GPIO_InitStruct.Mode = GPIO_MODE_INPUT;
  GPIO_InitStruct.Pull = GPIO_NOPULL;
  HAL_GPIO_Init(B1_GPIO_Port, &GPIO_InitStruct);

  /*Configure GPIO pins : SPI1_SCK_Pin SPI1_MISO_Pin SPI1_MISOA7_Pin */
  GPIO_InitStruct.Pin = SPI1_SCK_Pin|SPI1_MISO_Pin|SPI1_MISOA7_Pin;
  GPIO_InitStruct.Mode = GPIO_MODE_AF_PP;
  GPIO_InitStruct.Pull = GPIO_NOPULL;
  GPIO_InitStruct.Speed = GPIO_SPEED_FREQ_HIGH;
  GPIO_InitStruct.Alternate = GPIO_AF5_SPI1;
  HAL_GPIO_Init(GPIOA, &GPIO_InitStruct);

  /*Configure GPIO pins : DM_Pin DP_Pin */
  GPIO_InitStruct.Pin = DM_Pin|DP_Pin;
  GPIO_InitStruct.Mode = GPIO_MODE_AF_PP;
  GPIO_InitStruct.Pull = GPIO_NOPULL;
  GPIO_InitStruct.Speed = GPIO_SPEED_FREQ_HIGH;
  GPIO_InitStruct.Alternate = GPIO_AF14_USB;
  HAL_GPIO_Init(GPIOA, &GPIO_InitStruct);

}

void _Error_Handler(char *file, int line)
{
  while(1)
  {
  }
}

/************************ (C) COPYRIGHT STMicroelectronics *****END OF FILE****/
